# Sonata System register map
Vendor: lowRISC; File version: 0.1
CPU: Ibex r0p1, little endian, no MPU, no FPU, VTOR, 2 interrupt priority bits, 1 interrupts
Registers are 32-bit, read-write, no defined reset value unless marked. A register's access mark holds for its fields unless they carry their own. Offsets are from the block's base; [hi:lo] are bit positions; {n}, {i} and the like mark numbered series.

## USBDEV — USB 2.0 Full Speed device interface (12 Mbit/s)
Base 0x80400000
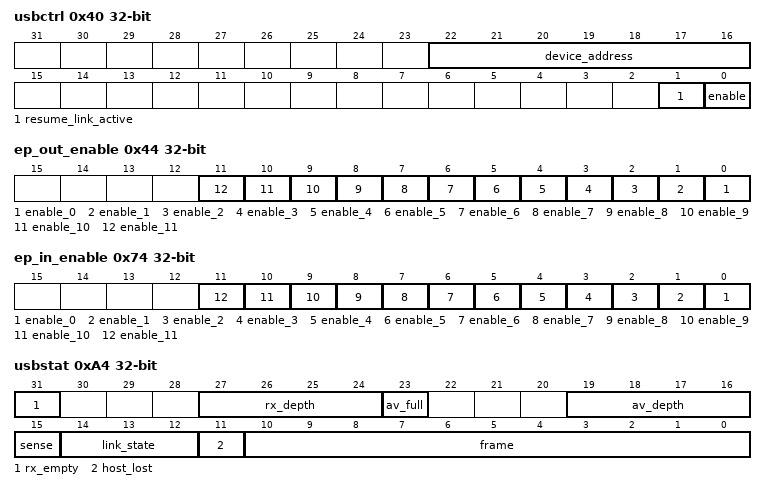
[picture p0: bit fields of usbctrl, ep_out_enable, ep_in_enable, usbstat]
0x40 usbctrl — USB Control
  [22:16] device_address — Device address set by host (this should be copied fromthe Set Device ID SETUP packet).This will be zeroed by the hardware when the link resets.
  [1] resume_link_active — Write a 1 to this bit to instruct usbdev to jump to the LinkResuming state.The write will only have an effect when the device is in the LinkPowered state.Its intention is to handle a resume-from-suspend event after the IP has been powered down.
  [0] enable — Set to connect the USB interface (i.e. assert the pullup).
0x44 ep_out_enable — Enable an endpoint to respond to transactions in the downstream direction.Note that as the default endpoint, endpoint 0 must be enabled in both the IN and OUT directions before enabling the USB interface to connect.
  [n] enable_{n} (n=0..11) — This bit must be set to enable downstream transactions to be received on the endpoint and elicit responses.If the bit is clear, any SETUP or OUT packets sent to the endpoint will be ignored.
0x74 ep_in_enable — Enable an endpoint to respond to transactions in the upstream direction.Note that as the default endpoint, endpoint 0 must be enabled in both the IN and OUT directions before enabling the USB interface to connect.
  [n] enable_{n} (n=0..11) — This bit must be set to enable upstream transactions to be received on the endpoint and elicit responses.If the bit is clear then any IN packets sent to the endpoint will be ignored.
0xA4 usbstat ro — USB Status
  [31] rx_empty — Received Buffer FIFO is empty.
  [27:24] rx_depth — Number of buffers in the Received Buffer FIFO.These buffers have packets that have been received andshould be popped from the FIFO and processed.
  [23] av_full — Available Buffer FIFO is full.
  [19:16] av_depth — Number of buffers in the Available Buffer FIFO.These buffers are available for receiving packets.
  [15] sense — Reflects the state of the sense pin.1 indicates that the host is providing VBUS.Note that this bit always shows the state of the actual pin and does not take account of the override control.
  [14:12] link_state — State of USB link, decoded from line.
  [11] host_lost — Start of frame not received from host for 4.096 ms and the line is active.
  [10:0] frame — Frame index received from host. On an active link, this will increment every milisecond.
0xA8 avbuffer wo — Available Buffer FIFO
  [4:0] buffer — This field contains the buffer ID being passed to the USB receive engine.If the Available Buffer FIFO is full, any write operations are discarded.
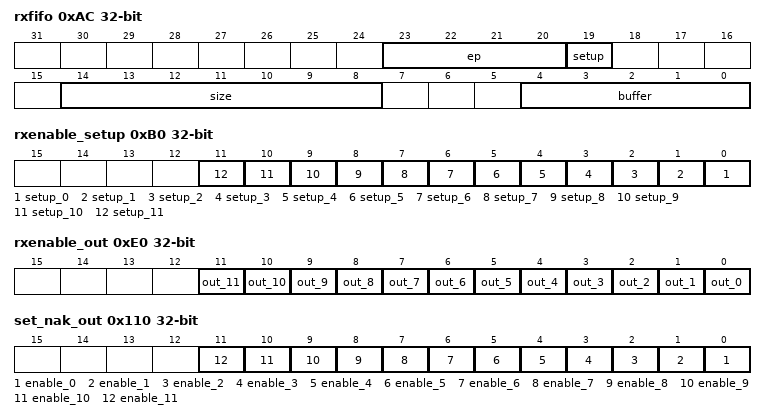
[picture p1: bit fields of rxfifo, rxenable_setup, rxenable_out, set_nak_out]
0xAC rxfifo ro — Received Buffer FIFO
  [23:20] ep — This field contains the endpoint ID to which the packet was directed.
  [19] setup — This bit indicates if the received transaction is of type SETUP (1) or OUT (0).
  [14:8] size — This field contains the data length in bytes of the packet written to the buffer.
  [4:0] buffer — This field contains the buffer ID that data was received into.On read the buffer ID is popped from the Received Buffer FIFO and returned to software.
0xB0 rxenable_setup — Receive SETUP transaction enable
  [n] setup_{n} (n=0..11) — This bit must be set to enable SETUP transactions to bereceived on the endpoint. If the bit is clear then aSETUP packet will be ignored. The bit should be set forcontrol endpoints (and only control endpoints).
0xE0 rxenable_out — Receive OUT transaction enable
  [n] out_{n} (n=0..11) — This bit must be set to enable OUT transactions to be received on the endpoint.If the bit is clear then an OUT request will be responded to with a NAK, if the endpoint is enabled.If set_nak_out for this endpoint is set, hardware will clear this bit whenever an OUT transaction is received on this endpoint.Software must set this bit again to receive the next OUT transaction.Until that happens, hardware will continue to NAK any OUT transaction to this endpoint.
0x110 set_nak_out — Set NAK after OUT transactions
  [n] enable_{n} (n=0..11) — When this bit is set, hardware will clear this endpoint's rxenable_out bit whenever an OUT transaction is received on this endpoint.This bit should not be changed while the endpoint is active.
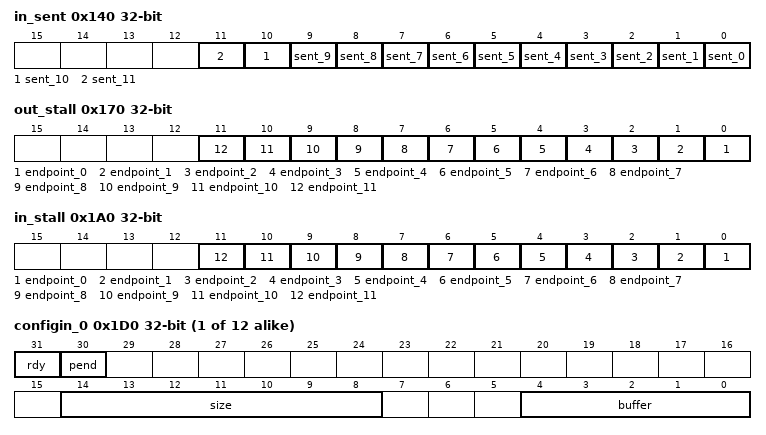
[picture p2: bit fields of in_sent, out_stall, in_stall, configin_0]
0x140 in_sent — IN Transaction Sent
  [n] sent_{n} (n=0..11) — This bit will be set when the ACK is received fromthe host to indicate successful packet deliveryas part of an IN transaction.
0x170 out_stall — OUT Endpoint STALL control
  [n] endpoint_{n} (n=0..11) — If this bit is set then an OUT transaction to this endpoint will elicit a STALL handshake, when a non-isochronous endpoint is enabled.If the configuration has both STALL and NAK enabled, the STALL handshake will take priority.Note that SETUP transactions are always either accepted or ignored.For endpoints that accept SETUP transactions, a SETUP packet will clear the STALL flag on endpoints for both the IN and OUT directions.
0x1A0 in_stall — IN Endpoint STALL control
  [n] endpoint_{n} (n=0..11) — If this bit is set then an IN transaction to this endpoint will elicit a STALL handshake, when a non-isochronous endpoint is enabled.If the configuration has both STALL and NAK enabled, the STALL handshake will take priority.Note that SETUP transactions are always either accepted or ignored.For endpoints that accept SETUP transactions, a SETUP packet will clear the STALL flag on endpoints for both the IN and OUT directions.
{0x1D0+4i} configin_{i} (i=0..11) — Configure IN Transaction
  [31] rdy — This bit should be set to indicate the buffer is ready for sending.It will be cleared when the ACK is received indicating the host has accepted the data.This bit will also be cleared if an enabled SETUP transaction is received on the endpoint.This allows use of the IN channel for transfer of SETUP information.The original buffer must be resubmitted after the SETUP sequence is complete.A link reset also clears the bit.In either of the cases where the hardware cancels the transaction it will also set the pend bit.
  [30] pend — This bit indicates a pending transaction was canceled by the hardware.The bit is set when the rdy bit is cleared by hardware because of aSETUP packet being received or a link reset being detected.The bit remains set until cleared by being written with a 1.
  [14:8] size — The number of bytes to send from the buffer.If this is 0 then a CRC only packet is sent.If this is greater than 64 then 64 bytes are sent.
  [4:0] buffer — The buffer ID containing the data to send when an IN transaction is received on the endpoint.
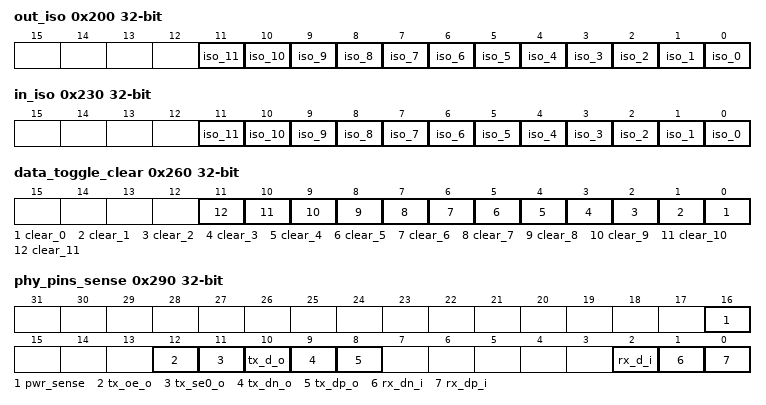
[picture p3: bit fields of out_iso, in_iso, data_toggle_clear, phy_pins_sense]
0x200 out_iso — OUT Endpoint isochronous setting
  [n] iso_{n} (n=0..11) — If this bit is set then the endpoint will be treated as an isochronous endpoint.No handshake packet will be sent for an OUT transaction.Note that if a rxenable_setup is set for this endpoint's number, this bit will not take effect.Control endpoint configuration trumps isochronous endpoint configuration.
0x230 in_iso — IN Endpoint isochronous setting
  [n] iso_{n} (n=0..11) — If this bit is set then the endpoint will be treated as an isochronous endpoint.No handshake packet will be expected for an IN transaction.Note that if a rxenable_setup is set for this endpoint's number, this bit will not take effect.Control endpoint configuration trumps isochronous endpoint configuration.
0x260 data_toggle_clear wo — Clear the data toggle flag
  [n] clear_{n} (n=0..11) — Writing 1 to this bit will clear the data toggle bit for this endpoint to Data0 in both IN and OUT directions.The register must no be written again within 200 ns.
0x290 phy_pins_sense ro — USB PHY pins sense.This register can be used to read out the state of the USB device inputs and outputs from software.This is designed to be used for debugging purposes or during chip testing.
  [16] pwr_sense — USB power sense signal.
  [12] tx_oe_o — USB OE output (readback).
  [11] tx_se0_o — USB single-ended zero output (readback).
  [10] tx_d_o — USB transmit data value (readback).
  [9] tx_dn_o — USB transmit D- output (readback).
  [8] tx_dp_o — USB transmit D+ output (readback).
  [2] rx_d_i — USB data input from an external differential receiver, if available.
  [1] rx_dn_i — USB D- input.
  [0] rx_dp_i — USB D+ input.
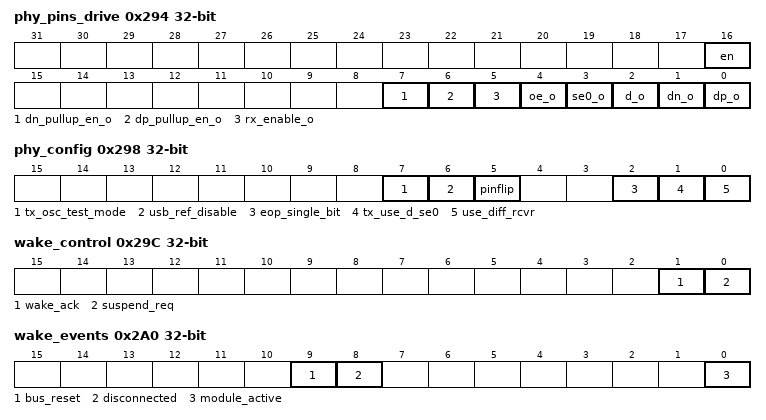
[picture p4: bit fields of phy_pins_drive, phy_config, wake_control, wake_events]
0x294 phy_pins_drive — USB PHY pins drive.This register can be used to control the USB device inputs and outputs from software.This is designed to be used for debugging purposes or during chip testing.
  [16] en — 0: Outputs are controlled by the hardware block.1: Outputs are controlled with this register.
  [7] dn_pullup_en_o — USB D- pullup enable output.
  [6] dp_pullup_en_o — USB D+ pullup enable output.
  [5] rx_enable_o — Enable differential receiver.
  [4] oe_o — USB OE output.
  [3] se0_o — USB single-ended zero output.
  [2] d_o — USB transmit data output, encoding K and J when se0_o is 0.
  [1] dn_o — USB transmit D- output, used with dp_o.
  [0] dp_o — USB transmit D+ output, used with dn_o.
0x298 phy_config — USB PHY Configuration
  [7] tx_osc_test_mode — Disable (0) or enable (1) oscillator test mode.If enabled, the device constantly transmits a J/K pattern, which is useful for testing the USB clock.Note that while in oscillator test mode, the device no longer receives SOFs and consequently does not generate the reference signal for clock synchronization.The clock might drift off.
  [6] usb_ref_disable — 0: Enable reference signal generation for clock synchronization, 1: disable it by forcing the associated signals to zero.
  [5] pinflip — Flip the D+/D- pins.Particularly useful if D+/D- are mapped to SBU1/SBU2 pins of USB-C.
  [2] eop_single_bit — Recognize a single SE0 bit as an end of packet, otherwise two successive bits are required.
  [1] tx_use_d_se0 — If 1, select the d and se0 TX interface.If 0, select the dp and dn TX interface.This directly controls the output pin of the same name.It is intended to be used to enable the use of a variety of external transceivers, to select an encoding that matches the transceiver.
  [0] use_diff_rcvr — Detect received K and J symbols from the usb_rx_d signal, which must be driven from an external differential receiver.If 1, make use of the usb_rx_d input.If 0, the usb_rx_d input is ignored and the usb_rx_dp and usb_rx_dn pair are used to detect K and J (useful for some environments, but will be unlikely to pass full USB compliance).Regardless of the state of this field usb_rx_dp and usb_rx_dn are always used to detect SE0.This bit also feeds the rx_enable pin, activating the receiver when the device is not suspended.
0x29C wake_control wo — USB wake module control for suspend / resume
  [1] wake_ack — Wake acknowledgement.Signal to the wake detection module that it may release control of the pull-ups back to the main block and return to an inactive state.The release back to normal state may not happen immediately.The status can be confirmed via wake_events.module_active.Note that this bit can also be used without powering down, such as when usbdev detects resume signaling before transitions to low power states have begun.
  [0] suspend_req — Suspend request to the wake detection module.Trigger the wake detection module to begin monitoring for wake-from-suspend events.When written with a 1, the wake detection module will activate.Activation may not happen immediately, and its status can be verified by checking wake_events.module_active.
0x2A0 wake_events ro — USB wake module events and debug
  [9] bus_reset — USB aon wake module detected a bus reset while monitoring events.
  [8] disconnected — USB aon wake module detected VBUS was interrupted while monitoring events.
  [0] module_active — USB aon wake module is active, monitoring events and controlling the pull-ups.
